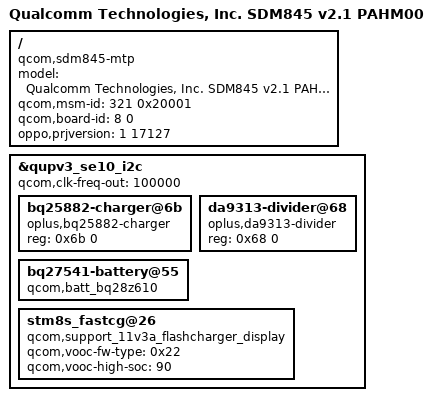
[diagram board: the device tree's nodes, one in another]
/* Copyright (c) 2017, The Linux Foundation. All rights reserved.
 *
 * This program is free software; you can redistribute it and/or modify
 * it under the terms of the GNU General Public License version 2 and
 * only version 2 as published by the Free Software Foundation.
 *
 * This program is distributed in the hope that it will be useful,
 * but WITHOUT ANY WARRANTY; without even the implied warranty of
 * MERCHANTABILITY or FITNESS FOR A PARTICULAR PURPOSE.  See the
 * GNU General Public License for more details.
 */

/dts-v1/;
/plugin/;

#include <dt-bindings/clock/qcom,gcc-sdm845.h>
#include <dt-bindings/clock/qcom,camcc-sdm845.h>
#include <dt-bindings/clock/qcom,dispcc-sdm845.h>
#include <dt-bindings/clock/qcom,rpmh.h>
#include <dt-bindings/interrupt-controller/arm-gic.h>

#include "sdm845-sde-display.dtsi"
#include "sdm845-mtp.dtsi"
#include "sdm845-audio-overlay.dtsi"
#include "sdm845-v2.1-findx-common.dtsi"

/ {
	model = "Qualcomm Technologies, Inc. SDM845 v2.1 PAHM00";
	compatible = "qcom,sdm845-mtp", "qcom,sdm845", "qcom,mtp";
	qcom,msm-id = <321 0x20001>;
	qcom,board-id = <8 0>;
	oppo,prjversion = <1 17127>;
};

&qupv3_se10_i2c {
	bq25882-charger@6b {
		status = "okay";
		compatible = "oplus,bq25882-charger";
		reg = <0x6b 0>;
	};

	da9313-divider@68 {
		status = "okay";
		compatible = "oplus,da9313-divider";
		reg = <0x68 0>;
	};

	bq27541-battery@55 {
		qcom,batt_bq28z610;
	};

	stm8s_fastcg@26 {
		qcom,support_11v3a_flashcharger_display;
		qcom,vooc-fw-type = <0x22>; // 5A
		qcom,vooc-high-soc = <90>;
	};
};

&qupv3_se10_i2c {
    qcom,clk-freq-out = <100000>;
};
